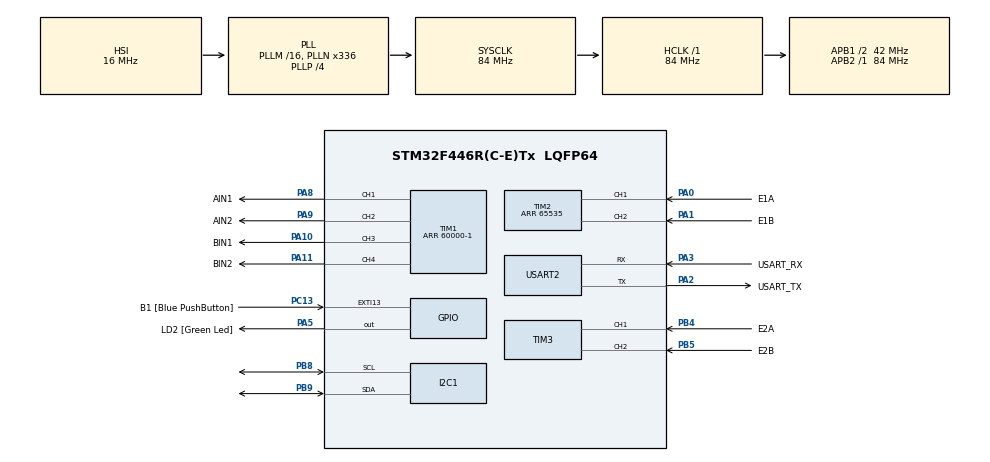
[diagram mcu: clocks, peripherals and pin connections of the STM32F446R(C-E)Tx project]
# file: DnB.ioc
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Dma.Request0=USART2_RX
Dma.Request1=USART2_TX
Dma.USART2_RX.0.Direction=DMA_PERIPH_TO_MEMORY
Dma.USART2_RX.0.FIFOMode=DMA_FIFOMODE_DISABLE
Dma.USART2_RX.0.Instance=DMA1_Stream5
Dma.USART2_RX.0.MemDataAlignment=DMA_MDATAALIGN_BYTE
Dma.USART2_RX.0.MemInc=DMA_MINC_ENABLE
Dma.USART2_RX.0.Mode=DMA_CIRCULAR
Dma.USART2_RX.0.PeriphDataAlignment=DMA_PDATAALIGN_BYTE
Dma.USART2_RX.0.PeriphInc=DMA_PINC_DISABLE
Dma.USART2_RX.0.Priority=DMA_PRIORITY_LOW
Dma.USART2_TX.1.Direction=DMA_MEMORY_TO_PERIPH
Dma.USART2_TX.1.FIFOMode=DMA_FIFOMODE_DISABLE
Dma.USART2_TX.1.Instance=DMA1_Stream6
Dma.USART2_TX.1.MemDataAlignment=DMA_MDATAALIGN_BYTE
Dma.USART2_TX.1.MemInc=DMA_MINC_ENABLE
Dma.USART2_TX.1.Mode=DMA_CIRCULAR
Dma.USART2_TX.1.PeriphDataAlignment=DMA_PDATAALIGN_BYTE
Dma.USART2_TX.1.PeriphInc=DMA_PINC_DISABLE
Dma.USART2_TX.1.Priority=DMA_PRIORITY_LOW
Mcu.Family=STM32F4
Mcu.Name=STM32F446R(C-E)Tx
Mcu.Package=LQFP64
NVIC.DMA1_Stream5_IRQn=true\:0\:0\:false\:false\:true\:false\:true\:true
NVIC.DMA1_Stream6_IRQn=true\:0\:0\:false\:false\:true\:false\:true\:true
NVIC.PriorityGroup=NVIC_PRIORITYGROUP_0
NVIC.TIM1_BRK_TIM9_IRQn=true\:0\:0\:false\:false\:true\:true\:true\:true
NVIC.TIM1_TRG_COM_TIM11_IRQn=true\:0\:0\:false\:false\:true\:true\:true\:true
NVIC.TIM2_IRQn=true\:0\:0\:false\:false\:true\:true\:true\:true
NVIC.TIM3_IRQn=true\:0\:0\:false\:false\:true\:true\:true\:true
NVIC.USART2_IRQn=true\:0\:0\:false\:false\:false\:true\:true\:true
PA0-WKUP.GPIO_Label=E1A
PA0-WKUP.Signal=S_TIM2_CH1_ETR
PA1.GPIO_Label=E1B
PA1.Signal=S_TIM2_CH2
PA10.GPIO_Label=BIN1
PA10.Signal=S_TIM1_CH3
PA11.GPIO_Label=BIN2
PA11.Signal=S_TIM1_CH4
PA13.GPIO_Label=TMS
PA13.Mode=Serial_Wire
PA13.Signal=SYS_JTMS-SWDIO
PA14.GPIO_Label=TCK
PA14.Mode=Serial_Wire
PA14.Signal=SYS_JTCK-SWCLK
PA2.GPIO_Label=USART_TX
PA2.GPIO_Speed=GPIO_SPEED_FREQ_LOW
PA2.Mode=Asynchronous
PA2.Signal=USART2_TX
PA3.GPIO_Label=USART_RX
PA3.GPIO_Speed=GPIO_SPEED_FREQ_LOW
PA3.Mode=Asynchronous
PA3.Signal=USART2_RX
PA5.GPIO_Label=LD2 [Green Led]
PA5.Signal=GPIO_Output
PA8.GPIO_Label=AIN1
PA8.Signal=S_TIM1_CH1
PA9.GPIO_Label=AIN2
PA9.Signal=S_TIM1_CH2
PB3.GPIO_Label=SWO
PB3.Signal=SYS_JTDO-SWO
PB4.GPIO_Label=E2A
PB4.Signal=S_TIM3_CH1
PB5.GPIO_Label=E2B
PB5.Signal=S_TIM3_CH2
PB8.GPIO_Speed=GPIO_SPEED_FREQ_LOW
PB8.Mode=I2C
PB8.Signal=I2C1_SCL
PB9.GPIO_Speed=GPIO_SPEED_FREQ_LOW
PB9.Mode=I2C
PB9.Signal=I2C1_SDA
PC13.GPIO_Label=B1 [Blue PushButton]
PC13.GPIO_ModeDefaultEXTI=GPIO_MODE_IT_FALLING
PC13.Signal=GPXTI13
PC14-OSC32_IN.Mode=LSE-External-Oscillator
PC14-OSC32_IN.Signal=RCC_OSC32_IN
PC15-OSC32_OUT.Mode=LSE-External-Oscillator
PC15-OSC32_OUT.Signal=RCC_OSC32_OUT
PH0-OSC_IN.Mode=HSE-External-Oscillator
PH0-OSC_IN.Signal=RCC_OSC_IN
PH1-OSC_OUT.Mode=HSE-External-Oscillator
PH1-OSC_OUT.Signal=RCC_OSC_OUT
ProjectManager.HeapSize=0x200
ProjectManager.StackSize=0x400
ProjectManager.TargetToolchain=STM32CubeIDE
RCC.48MHZClocksFreq_Value=84000000
RCC.AHBFreq_Value=84000000
RCC.APB1CLKDivider=RCC_HCLK_DIV2
RCC.APB1Freq_Value=42000000
RCC.APB1TimFreq_Value=84000000
RCC.APB2Freq_Value=84000000
RCC.APB2TimFreq_Value=84000000
RCC.CortexFreq_Value=84000000
RCC.FLatency-AdvancedSettings=FLASH_LATENCY_2
RCC.HCLKFreq_Value=84000000
RCC.HSE_VALUE=8000000
RCC.HSI_VALUE=16000000
RCC.PLLN=336
RCC.PLLP=RCC_PLLP_DIV4
RCC.SYSCLKFreq_VALUE=84000000
RCC.SYSCLKSource=RCC_SYSCLKSOURCE_PLLCLK
RCC.USBFreq_Value=168000000
RCC.VCOOutputFreq_Value=336000000
SH.S_TIM1_CH1.0=TIM1_CH1,PWM Generation1 CH1
SH.S_TIM1_CH2.0=TIM1_CH2,PWM Generation2 CH2
SH.S_TIM1_CH3.0=TIM1_CH3,PWM Generation3 CH3
SH.S_TIM1_CH4.0=TIM1_CH4,PWM Generation4 CH4
SH.S_TIM2_CH1_ETR.0=TIM2_CH1,Encoder_Interface
SH.S_TIM2_CH2.0=TIM2_CH2,Encoder_Interface
SH.S_TIM3_CH1.0=TIM3_CH1,Encoder_Interface
SH.S_TIM3_CH2.0=TIM3_CH2,Encoder_Interface
TIM1.Channel-PWM\ Generation1\ CH1=TIM_CHANNEL_1
TIM1.Channel-PWM\ Generation2\ CH2=TIM_CHANNEL_2
TIM1.Channel-PWM\ Generation3\ CH3=TIM_CHANNEL_3
TIM1.Channel-PWM\ Generation4\ CH4=TIM_CHANNEL_4
TIM1.Period=60000-1
TIM2.EncoderMode=TIM_ENCODERMODE_TI12
TIM2.Period=65535
TIM3.EncoderMode=TIM_ENCODERMODE_TI12
TIM9.Period=10000-1
TIM9.Prescaler=84-1
USART2.VirtualMode=VM_ASYNC
VP_TIM1_VS_ClockSourceINT.Mode=Internal
VP_TIM9_VS_ClockSourceINT.Mode=Internal
board=NUCLEO-F446RE

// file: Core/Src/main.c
/* USER CODE BEGIN Header */
/**
  ******************************************************************************
  * @file           : main.c
  * @brief          : Main program body
  ******************************************************************************
  * @attention
  *
  * Copyright (c) 2025 STMicroelectronics.
  * All rights reserved.
  *
  * This software is licensed under terms that can be found in the LICENSE file
  * in the root directory of this software component.
  * If no LICENSE file comes with this software, it is provided AS-IS.
  *
  ******************************************************************************
  */
/* USER CODE END Header */
#include "main.h"
#include "dma.h"
#include "i2c.h"
#include "tim.h"
#include "usart.h"
#include "gpio.h"

/* USER CODE BEGIN Includes */
#include "car.h"
#include "communication.h"
/* USER CODE END Includes */

/* USER CODE BEGIN PV */
extern Car car;
/* USER CODE END PV */

void SystemClock_Config(void);

int main(void)
{

  /* MCU Configuration--------------------------------------------------------*/

  /* Reset of all peripherals, Initializes the Flash interface and the Systick. */
  HAL_Init();

  /* Configure the system clock */
  SystemClock_Config();

  /* Initialize all configured peripherals */
  MX_GPIO_Init();
  MX_DMA_Init();
  MX_USART2_UART_Init();
  MX_TIM1_Init();
  MX_TIM2_Init();
  MX_TIM3_Init();
  MX_TIM9_Init();
  MX_I2C1_Init();
  /* USER CODE BEGIN 2 */
  car = newCar();
  HAL_TIM_Base_Start_IT(&htim9);

  /* USER CODE END 2 */

  /* Infinite loop */
  while (1)
  {

    /* USER CODE BEGIN 3 */
    car.motor_l.Move(&car.motor_l,0,50);
    car.motor_r.Move(&car.motor_r,0,50);
    car.imu.Get_Data(&car.imu);
//    uart_printf(&huart2,"%d,%f,%f\n",car.encoder_l.rpm,car.motor_l.setRPM,car.motor_r.pid.out);
    uart_printf(&huart2,"%f,%d\n",car.imu.roll,car.encoder_l.count);
  }
  /* USER CODE END 3 */
}

void SystemClock_Config(void)
{
  RCC_OscInitTypeDef RCC_OscInitStruct = {0};
  RCC_ClkInitTypeDef RCC_ClkInitStruct = {0};

  /** Configure the main internal regulator output voltage
  */
  __HAL_RCC_PWR_CLK_ENABLE();
  __HAL_PWR_VOLTAGESCALING_CONFIG(PWR_REGULATOR_VOLTAGE_SCALE3);

  /** Initializes the RCC Oscillators according to the specified parameters
  * in the RCC_OscInitTypeDef structure.
  */
  RCC_OscInitStruct.OscillatorType = RCC_OSCILLATORTYPE_HSI;
  RCC_OscInitStruct.HSIState = RCC_HSI_ON;
  RCC_OscInitStruct.HSICalibrationValue = RCC_HSICALIBRATION_DEFAULT;
  RCC_OscInitStruct.PLL.PLLState = RCC_PLL_ON;
  RCC_OscInitStruct.PLL.PLLSource = RCC_PLLSOURCE_HSI;
  RCC_OscInitStruct.PLL.PLLM = 16;
  RCC_OscInitStruct.PLL.PLLN = 336;
  RCC_OscInitStruct.PLL.PLLP = RCC_PLLP_DIV4;
  RCC_OscInitStruct.PLL.PLLQ = 2;
  RCC_OscInitStruct.PLL.PLLR = 2;
  if (HAL_RCC_OscConfig(&RCC_OscInitStruct) != HAL_OK)
  {
    Error_Handler();
  }

  /** Initializes the CPU, AHB and APB buses clocks
  */
  RCC_ClkInitStruct.ClockType = RCC_CLOCKTYPE_HCLK|RCC_CLOCKTYPE_SYSCLK
                              |RCC_CLOCKTYPE_PCLK1|RCC_CLOCKTYPE_PCLK2;
  RCC_ClkInitStruct.SYSCLKSource = RCC_SYSCLKSOURCE_PLLCLK;
  RCC_ClkInitStruct.AHBCLKDivider = RCC_SYSCLK_DIV1;
  RCC_ClkInitStruct.APB1CLKDivider = RCC_HCLK_DIV2;
  RCC_ClkInitStruct.APB2CLKDivider = RCC_HCLK_DIV1;

  if (HAL_RCC_ClockConfig(&RCC_ClkInitStruct, FLASH_LATENCY_2) != HAL_OK)
  {
    Error_Handler();
  }
}

void Error_Handler(void)
{
  __disable_irq();
  while (1)
  {
  }
}
